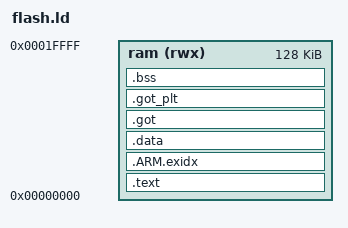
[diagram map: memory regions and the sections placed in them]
OUTPUT_FORMAT("elf32-littlearm", "elf32-littlearm", "elf32-littlearm")
OUTPUT_ARCH(arm)
SEARCH_DIR(.)

/* The kernel will only approve programs with a max size of ~ 100 kBytes */
MEMORY
{
    ram (rwx)    : ORIGIN = 0x00000000, LENGTH = 0x00020000
}

SECTIONS
{
    .text :
    {
        . = ALIGN(4);
        _sfixed = .;
        KEEP(*(.info .info.*))
        *(.text .text.* .gnu.linkonce.t.*)
        *(.glue_7t) *(.glue_7)
        *(.rodata .rodata* .gnu.linkonce.r.*)
        *(.ARM.extab* .gnu.linkonce.armextab.*)

        . = ALIGN(4);
        KEEP(*(.init))
        . = ALIGN(4);
        __preinit_array_start = .;
        KEEP (*(.preinit_array))
        __preinit_array_end = .;

        . = ALIGN(4);
        __init_array_start = .;
        KEEP (*(SORT(.init_array.*)))
        KEEP (*(.init_array))
        __init_array_end = .;

        . = ALIGN(4);
        KEEP (*crtbegin.o(.ctors))
        KEEP (*(EXCLUDE_FILE (*crtend.o) .ctors))
        KEEP (*(SORT(.ctors.*)))
        KEEP (*crtend.o(.ctors))
        . = ALIGN(4);
        KEEP(*(.fini))

        . = ALIGN(4);
        __fini_array_start = .;
        KEEP (*(.fini_array))
        KEEP (*(SORT(.fini_array.*)))
        __fini_array_end = .;

        KEEP (*crtbegin.o(.dtors))
        KEEP (*(EXCLUDE_FILE (*crtend.o) .dtors))
        KEEP (*(SORT(.dtors.*)))
        KEEP (*crtend.o(.dtors))

        . = ALIGN(4);
        _efixed = .;
    } > ram

    PROVIDE_HIDDEN (__exidx_start = .);
    .ARM.exidx :
    {	
      *(.ARM.exidx* .gnu.linkonce.armexidx.*)
    } > ram
    PROVIDE_HIDDEN (__exidx_end = .);

    . = ALIGN(4);
    _etext = .;

    .data :
    {
        . = ALIGN(4);
        _srelocate = .;
        *(.ramfunc .ramfunc.*);
        *(.data .data.*);
        . = ALIGN(4);
        _erelocate = .;
    } > ram

	_sgot = .;
	.got : {*(.got .got.*);} > ram
	_egot = .;

	_sgot_plt = .;
	.got_plt : {*(.got.plt .got.plt.*);} > ram
	_egot_plt= .;

    .bss (NOLOAD) :
    {
        . = ALIGN(4);
        _sbss = . ;
        _szero = .;
        *(.bss .bss.*)
        *(COMMON)
        . = ALIGN(4);
        _ebss = . ;
        _ezero = .;
    } > ram

    . = ALIGN(4);
    _end = . ;
    _ram_end_ = ORIGIN(ram) + LENGTH(ram) - 1 ;
}
